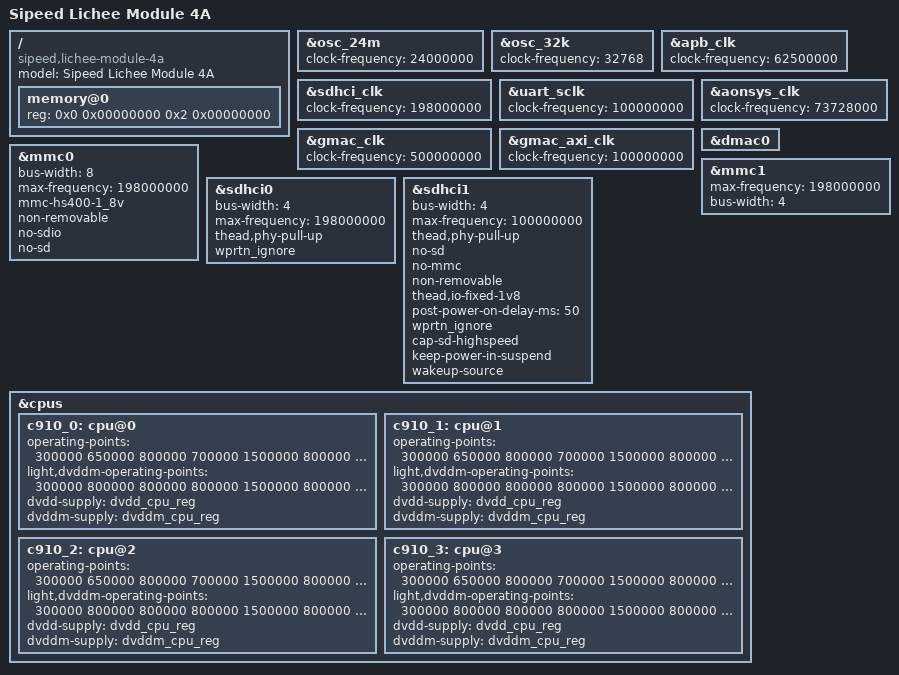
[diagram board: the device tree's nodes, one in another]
// SPDX-License-Identifier: (GPL-2.0 OR MIT)
/*
 * Copyright (C) 2023 Jisheng Zhang <jszhang@kernel.org>
 */

/dts-v1/;

#include "th1520.dtsi"

/ {
	model = "Sipeed Lichee Module 4A";
	compatible = "sipeed,lichee-module-4a", "thead,th1520";

	memory@0 {
		device_type = "memory";
		reg = <0x0 0x00000000 0x2 0x00000000>;
	};
};

&osc_24m {
	clock-frequency = <24000000>;
};

&osc_32k {
	clock-frequency = <32768>;
};

&apb_clk {
	clock-frequency = <62500000>;
};

&sdhci_clk {
	clock-frequency = <198000000>;
};

&uart_sclk {
	clock-frequency = <100000000>;
};

&gmac_clk {
	clock-frequency = <500000000>;
};

&gmac_axi_clk {
	clock-frequency = <100000000>;
};

&aonsys_clk {
	clock-frequency = <73728000>;
};

&dmac0 {
	status = "okay";
};

&mmc0 {
	bus-width = <8>;
	max-frequency = <198000000>;
	mmc-hs400-1_8v;
	non-removable;
	no-sdio;
	no-sd;
	status = "okay";
};

&mmc1 {
	max-frequency = <198000000>;
	bus-width = <4>;
	status = "okay";
};

&sdhci0 {
	bus-width = <4>;
	max-frequency = <198000000>;
	thead,phy-pull-up;
	wprtn_ignore;
	status = "okay";
};

&sdhci1 {
	bus-width = <4>;
	max-frequency = <100000000>;
	thead,phy-pull-up;
	no-sd;
	no-mmc;
	non-removable;
	thead,io-fixed-1v8;
	post-power-on-delay-ms = <50>;
	wprtn_ignore;
	cap-sd-highspeed;
	keep-power-in-suspend;
	wakeup-source;
	status = "okay";
};

&cpus {
	c910_0: cpu@0 {
		operating-points = <
			/* kHz    uV */
			300000	650000
			800000	700000
			1500000	800000
			1848000 1000000
		>;
		light,dvddm-operating-points = <
			/* kHz   uV */
			300000	800000
			800000	800000
			1500000	800000
			1848000 1000000
		>;
		dvdd-supply = <&dvdd_cpu_reg>;
		dvddm-supply = <&dvddm_cpu_reg>;
	};
	c910_1: cpu@1 {
		operating-points = <
			/* kHz    uV */
			300000	650000
			800000	700000
			1500000	800000
			1848000 1000000
		>;
		light,dvddm-operating-points = <
			/* kHz   uV */
			300000	800000
			800000	800000
			1500000	800000
			1848000 1000000
		>;
		dvdd-supply = <&dvdd_cpu_reg>;
		dvddm-supply = <&dvddm_cpu_reg>;
	};
	c910_2: cpu@2 {

		operating-points = <
			/* kHz    uV */
			300000	650000
			800000	700000
			1500000	800000
			1848000 1000000
		>;
		light,dvddm-operating-points = <
			/* kHz   uV */
			300000	800000
			800000	800000
			1500000	800000
			1848000 1000000
		>;
		dvdd-supply = <&dvdd_cpu_reg>;
		dvddm-supply = <&dvddm_cpu_reg>;
	};
	c910_3: cpu@3 {

		operating-points = <
			/* kHz    uV */
			300000	650000
			800000	700000
			1500000	800000
			1848000 1000000
		>;
		light,dvddm-operating-points = <
			/* kHz   uV */
			300000	800000
			800000	800000
			1500000	800000
			1848000 1000000
		>;
		dvdd-supply = <&dvdd_cpu_reg>;
		dvddm-supply = <&dvddm_cpu_reg>;
	};
};
